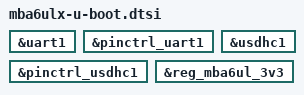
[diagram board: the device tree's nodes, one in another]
// SPDX-License-Identifier: (GPL-2.0-or-later OR MIT)
/*
 * Copyright (c) 2024-2026 TQ-Systems GmbH <u-boot@ew.tq-group.com>,
 * D-82229 Seefeld, Germany.
 * Author: Max Merchel
 */

&uart1 {
	bootph-pre-ram;
};

&pinctrl_uart1 {
	bootph-pre-ram;
};

&usdhc1 {
	bootph-pre-ram;
};

&pinctrl_usdhc1 {
	bootph-pre-ram;
};

&reg_mba6ul_3v3 {
	bootph-pre-ram;
};
